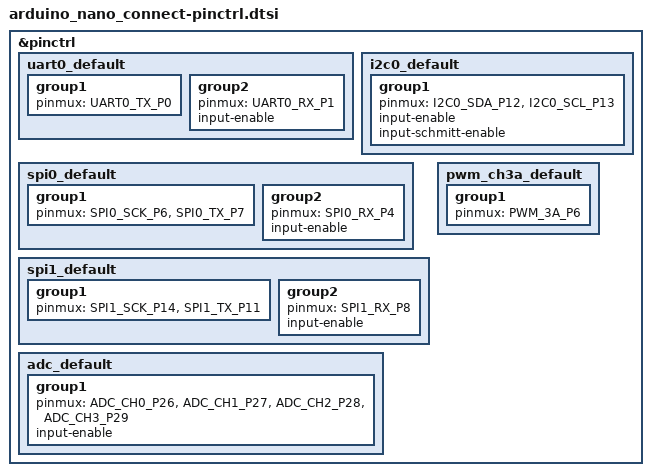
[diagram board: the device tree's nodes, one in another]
/*
 * Copyright (c) Arduino s.r.l. and/or its affiliated companies
 * SPDX-License-Identifier: Apache-2.0
 */

#include <zephyr/dt-bindings/pinctrl/rpi-pico-rp2040-pinctrl.h>

&pinctrl {
	uart0_default: uart0_default {
		group1 {
			pinmux = <UART0_TX_P0>;
		};

		group2 {
			pinmux = <UART0_RX_P1>;
			input-enable;
		};
	};

	i2c0_default: i2c0_default {
		group1 {
			pinmux = <I2C0_SDA_P12>, <I2C0_SCL_P13>;
			input-enable;
			input-schmitt-enable;
		};
	};

	spi0_default: spi0_default {
		/* Main SPI bus for user (directly exposed pins) */
		group1 {
			pinmux = <SPI0_SCK_P6>, <SPI0_TX_P7>;
		};

		group2 {
			pinmux = <SPI0_RX_P4>;
			input-enable;
		};
	};

	spi1_default: spi1_default {
		/* SPI bus to NINA WiFi module */
		group1 {
			pinmux = <SPI1_SCK_P14>, <SPI1_TX_P11>;
		};

		group2 {
			pinmux = <SPI1_RX_P8>;
			input-enable;
		};
	};

	adc_default: adc_default {
		group1 {
			pinmux = <ADC_CH0_P26>, <ADC_CH1_P27>, <ADC_CH2_P28>, <ADC_CH3_P29>;
			input-enable;
		};
	};

	pwm_ch3a_default: pwm_ch3a_default {
		group1 {
			pinmux = <PWM_3A_P6>;
		};
	};
};
